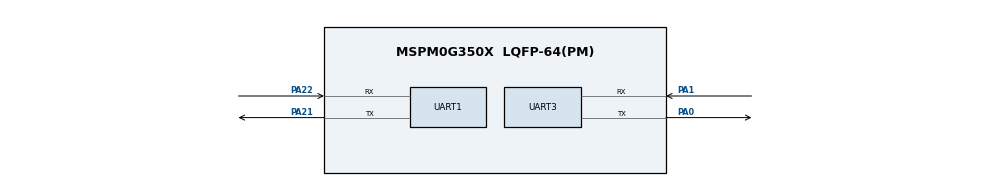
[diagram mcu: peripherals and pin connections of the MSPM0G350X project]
/**
 * @cliArgs --device "MSPM0G350X" --package "LQFP-64(PM)" --part "Default" --product "mspm0_sdk@2.01.00.03"
 * @versions {"tool":"1.20.0+3587"}
 */

/**
 * Import the modules used in this configuration.
 */
const GPIO   = scripting.addModule("/ti/driverlib/GPIO", {}, false);
const GPIO1  = GPIO.addInstance();
const GPIO2  = GPIO.addInstance();
const I2C    = scripting.addModule("/ti/driverlib/I2C", {}, false);
const I2C1   = I2C.addInstance();
const PWM    = scripting.addModule("/ti/driverlib/PWM", {}, false);
const PWM1   = PWM.addInstance();
const PWM2   = PWM.addInstance();
const SYSCTL = scripting.addModule("/ti/driverlib/SYSCTL");
const TIMER  = scripting.addModule("/ti/driverlib/TIMER", {}, false);
const TIMER1 = TIMER.addInstance();
const TIMER2 = TIMER.addInstance();
const UART   = scripting.addModule("/ti/driverlib/UART", {}, false);
const UART1  = UART.addInstance();
const UART2  = UART.addInstance();
const UART3  = UART.addInstance();

/**
 * Write custom configuration values to the imported modules.
 */
const gate7  = system.clockTree["MFCLKGATE"];
gate7.enable = true;

GPIO1.port                          = "PORTA";
GPIO1.$name                         = "GPIOA";
GPIO1.portSegment                   = "Lower";
GPIO1.associatedPins.create(4);
GPIO1.associatedPins[0].$name       = "AIN0";
GPIO1.associatedPins[0].ioStructure = "HS";
GPIO1.associatedPins[1].$name       = "AIN1";
GPIO1.associatedPins[1].ioStructure = "HS";
GPIO1.associatedPins[2].$name       = "BIN0";
GPIO1.associatedPins[2].ioStructure = "HS";
GPIO1.associatedPins[3].$name       = "BIN1";
GPIO1.associatedPins[3].ioStructure = "HS";

const Board = scripting.addModule("/ti/driverlib/Board", {}, false);

GPIO2.port                               = "PORTB";
GPIO2.portSegment                        = "Upper";
GPIO2.$name                              = "ENCODER";
GPIO2.associatedPins.create(4);
GPIO2.associatedPins[0].$name            = "E0A";
GPIO2.associatedPins[0].direction        = "INPUT";
GPIO2.associatedPins[0].interruptEn      = true;
GPIO2.associatedPins[0].polarity         = "FALL";
GPIO2.associatedPins[0].internalResistor = "PULL_UP";
GPIO2.associatedPins[0].assignedPin      = "19";
GPIO2.associatedPins[1].$name            = "E0B";
GPIO2.associatedPins[1].direction        = "INPUT";
GPIO2.associatedPins[1].assignedPin      = "18";
GPIO2.associatedPins[1].internalResistor = "PULL_UP";
GPIO2.associatedPins[2].$name            = "E1A";
GPIO2.associatedPins[2].direction        = "INPUT";
GPIO2.associatedPins[2].interruptEn      = true;
GPIO2.associatedPins[2].polarity         = "FALL";
GPIO2.associatedPins[2].assignedPin      = "17";
GPIO2.associatedPins[3].$name            = "E1B";
GPIO2.associatedPins[3].direction        = "INPUT";
GPIO2.associatedPins[3].ioStructure      = "SD";
GPIO2.associatedPins[3].assignedPin      = "16";
GPIO2.associatedPins[3].internalResistor = "PULL_UP";

I2C1.basicEnableController             = true;
I2C1.$name                             = "I2C_OLED";
I2C1.intController                     = ["ARBITRATION_LOST","NACK","RXFIFO_TRIGGER","RX_DONE","TX_DONE"];
I2C1.sdaPinConfig.$name                = "ti_driverlib_gpio_GPIOPinGeneric0";
I2C1.sdaPinConfig.hideOutputInversion  = scripting.forceWrite(false);
I2C1.sdaPinConfig.onlyInternalResistor = scripting.forceWrite(false);
I2C1.sdaPinConfig.passedPeripheralType = scripting.forceWrite("Digital");
I2C1.sclPinConfig.$name                = "ti_driverlib_gpio_GPIOPinGeneric1";
I2C1.sclPinConfig.hideOutputInversion  = scripting.forceWrite(false);
I2C1.sclPinConfig.onlyInternalResistor = scripting.forceWrite(false);
I2C1.sclPinConfig.passedPeripheralType = scripting.forceWrite("Digital");

PWM1.$name               = "PWM_0";
PWM1.timerCount          = 32000;
PWM1.timerStartTimer     = true;
PWM1.peripheral.$assign  = "TIMG7";
PWM1.PWM_CHANNEL_0.$name = "ti_driverlib_pwm_PWMTimerCC0";
PWM1.PWM_CHANNEL_1.$name = "ti_driverlib_pwm_PWMTimerCC1";
PWM1.ccp0PinConfig.$name = "ti_driverlib_gpio_GPIOPinGeneric6";
PWM1.ccp1PinConfig.$name = "ti_driverlib_gpio_GPIOPinGeneric7";

PWM2.$name               = "PWM_1";
PWM2.timerCount          = 32000;
PWM2.timerStartTimer     = true;
PWM2.peripheral.$assign  = "TIMG8";
PWM2.PWM_CHANNEL_0.$name = "ti_driverlib_pwm_PWMTimerCC2";
PWM2.PWM_CHANNEL_1.$name = "ti_driverlib_pwm_PWMTimerCC3";
PWM2.ccp0PinConfig.$name = "ti_driverlib_gpio_GPIOPinGeneric8";
PWM2.ccp1PinConfig.$name = "ti_driverlib_gpio_GPIOPinGeneric9";

SYSCTL.forceDefaultClkConfig = true;
SYSCTL.clockTreeEn           = true;

TIMER1.timerClkDiv                      = 8;
TIMER1.timerClkPrescale                 = 100;
TIMER1.timerPeriod                      = "10 ms";
TIMER1.timerMode                        = "PERIODIC";
TIMER1.interrupts                       = ["ZERO"];
TIMER1.$name                            = "ENCODER_TIM0";
TIMER1.timerStartTimer                  = true;
TIMER1.peripheral.$assignAllowConflicts = "TIMG0";

TIMER2.timerClkDiv        = 8;
TIMER2.timerClkPrescale   = 100;
TIMER2.timerPeriod        = "10 ms";
TIMER2.timerMode          = "PERIODIC";
TIMER2.interrupts         = ["ZERO"];
TIMER2.$name              = "ENCODER_TIM1";
TIMER2.timerStartTimer    = true;
TIMER2.peripheral.$assign = "TIMG6";

UART1.$name                            = "grayscale";
UART1.targetBaudRate                   = 115200;
UART1.enableFIFO                       = true;
UART1.rxFifoThreshold                  = "DL_UART_RX_FIFO_LEVEL_ONE_ENTRY";
UART1.enabledDMARXTriggers             = "DL_UART_DMA_INTERRUPT_RX";
UART1.enabledInterrupts                = ["DMA_DONE_RX"];
UART1.peripheral.rxPin.$assign         = "PA22";
UART1.peripheral.txPin.$assign         = "PA21";
UART1.txPinConfig.direction            = scripting.forceWrite("OUTPUT");
UART1.txPinConfig.hideOutputInversion  = scripting.forceWrite(false);
UART1.txPinConfig.onlyInternalResistor = scripting.forceWrite(false);
UART1.txPinConfig.passedPeripheralType = scripting.forceWrite("Digital");
UART1.txPinConfig.$name                = "ti_driverlib_gpio_GPIOPinGeneric2";
UART1.rxPinConfig.hideOutputInversion  = scripting.forceWrite(false);
UART1.rxPinConfig.onlyInternalResistor = scripting.forceWrite(false);
UART1.rxPinConfig.passedPeripheralType = scripting.forceWrite("Digital");
UART1.rxPinConfig.$name                = "ti_driverlib_gpio_GPIOPinGeneric3";
UART1.DMA_CHANNEL_RX.$name             = "DMA_CH0";
UART1.DMA_CHANNEL_RX.addressMode       = "f2b";
UART1.DMA_CHANNEL_RX.srcLength         = "BYTE";
UART1.DMA_CHANNEL_RX.dstLength         = "BYTE";
UART1.DMA_CHANNEL_RX.transferMode      = "FULL_CH_REPEAT_SINGLE";

UART2.$name                            = "Gyroscpe";
UART2.txPinConfig.direction            = scripting.forceWrite("OUTPUT");
UART2.txPinConfig.hideOutputInversion  = scripting.forceWrite(false);
UART2.txPinConfig.onlyInternalResistor = scripting.forceWrite(false);
UART2.txPinConfig.passedPeripheralType = scripting.forceWrite("Digital");
UART2.txPinConfig.$name                = "ti_driverlib_gpio_GPIOPinGeneric4";
UART2.rxPinConfig.hideOutputInversion  = scripting.forceWrite(false);
UART2.rxPinConfig.onlyInternalResistor = scripting.forceWrite(false);
UART2.rxPinConfig.passedPeripheralType = scripting.forceWrite("Digital");
UART2.rxPinConfig.$name                = "ti_driverlib_gpio_GPIOPinGeneric5";

UART3.uartClkSrc                       = "MFCLK";
UART3.$name                            = "UART_0";
UART3.enableFIFO                       = true;
UART3.rxFifoThreshold                  = "DL_UART_RX_FIFO_LEVEL_ONE_ENTRY";
UART3.txFifoThreshold                  = "DL_UART_TX_FIFO_LEVEL_ONE_ENTRY";
UART3.enabledDMATXTriggers             = "DL_UART_DMA_INTERRUPT_TX";
UART3.enabledInterrupts                = ["DMA_DONE_TX","EOT_DONE"];
UART3.peripheral.rxPin.$assign         = "PA1";
UART3.peripheral.txPin.$assign         = "PA0";
UART3.txPinConfig.$name                = "ti_driverlib_gpio_GPIOPinGeneric10";
UART3.txPinConfig.direction            = scripting.forceWrite("OUTPUT");
UART3.txPinConfig.hideOutputInversion  = scripting.forceWrite(false);
UART3.txPinConfig.onlyInternalResistor = scripting.forceWrite(false);
UART3.txPinConfig.passedPeripheralType = scripting.forceWrite("Digital");
UART3.rxPinConfig.$name                = "ti_driverlib_gpio_GPIOPinGeneric11";
UART3.rxPinConfig.hideOutputInversion  = scripting.forceWrite(false);
UART3.rxPinConfig.onlyInternalResistor = scripting.forceWrite(false);
UART3.rxPinConfig.passedPeripheralType = scripting.forceWrite("Digital");
UART3.DMA_CHANNEL_TX.$name             = "DMA_CH1";
UART3.DMA_CHANNEL_TX.addressMode       = "b2f";
UART3.DMA_CHANNEL_TX.srcLength         = "BYTE";
UART3.DMA_CHANNEL_TX.dstLength         = "BYTE";

/**
 * Pinmux solution for unlocked pins/peripherals. This ensures that minor changes to the automatic solver in a future
 * version of the tool will not impact the pinmux you originally saw.  These lines can be completely deleted in order to
 * re-solve from scratch.
 */
GPIO1.associatedPins[0].pin.$suggestSolution     = "PA9";
GPIO1.associatedPins[1].pin.$suggestSolution     = "PA14";
GPIO1.associatedPins[2].pin.$suggestSolution     = "PA13";
GPIO1.associatedPins[3].pin.$suggestSolution     = "PA12";
Board.peripheral.$suggestSolution                = "DEBUGSS";
Board.peripheral.swclkPin.$suggestSolution       = "PA20";
Board.peripheral.swdioPin.$suggestSolution       = "PA19";
GPIO2.associatedPins[0].pin.$suggestSolution     = "PB19";
GPIO2.associatedPins[1].pin.$suggestSolution     = "PB18";
GPIO2.associatedPins[2].pin.$suggestSolution     = "PB17";
GPIO2.associatedPins[3].pin.$suggestSolution     = "PB16";
I2C1.peripheral.$suggestSolution                 = "I2C0";
I2C1.peripheral.sdaPin.$suggestSolution          = "PA10";
I2C1.peripheral.sclPin.$suggestSolution          = "PA11";
PWM1.peripheral.ccp0Pin.$suggestSolution         = "PA26";
PWM1.peripheral.ccp1Pin.$suggestSolution         = "PA24";
PWM2.peripheral.ccp0Pin.$suggestSolution         = "PA23";
PWM2.peripheral.ccp1Pin.$suggestSolution         = "PA2";
UART1.peripheral.$suggestSolution                = "UART2";
UART1.DMA_CHANNEL_RX.peripheral.$suggestSolution = "DMA_CH1";
UART2.peripheral.$suggestSolution                = "UART1";
UART2.peripheral.rxPin.$suggestSolution          = "PA18";
UART2.peripheral.txPin.$suggestSolution          = "PA17";
UART3.peripheral.$suggestSolution                = "UART0";
UART3.DMA_CHANNEL_TX.peripheral.$suggestSolution = "DMA_CH0";
